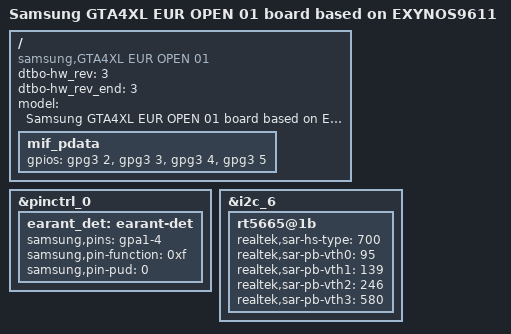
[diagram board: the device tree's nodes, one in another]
/*
 * SAMSUNG EXYNOS9610 board device tree source
 *
 * Copyright (c) 2018 Samsung Electronics Co., Ltd.
 *		http://www.samsung.com
 *
 * This program is free software; you can redistribute it and/or modify
 * it under the terms of the GNU General Public License version 2 as
 * published by the Free Software Foundation.
 */

/dts-v1/;
/plugin/;

#include "exynos9611-gta4xl_common.dtsi"
#include "battery_data_gta4xl_common.dtsi"
#include "exynos9611-gta4xl_sensorhub_00.dtsi"
#include "exynos9611-gta4xl_eur_open_gpio_03.dtsi"

/ {
	compatible = "samsung,GTA4XL EUR OPEN 01", "samsung,EXYNOS9611";

	dtbo-hw_rev = <3>;
    dtbo-hw_rev_end = <3>;


	fragment@model {
		target-path = "/";
		__overlay__ {
			#address-cells = <2>;
			#size-cells = <1>;

			model = "Samsung GTA4XL EUR OPEN 01 board based on EXYNOS9611";

			mif_pdata {
				/* GPIOs for HW REV */
				/* XGPIO26-AP_REV0, XGPIO27-AP_REV1, XGPIO28-AP_REV2, XGPIO29-AP_REV3 */
				gpios = <&gpg3 2 0>, <&gpg3 3 0>, <&gpg3 4 0>, <&gpg3 5 0>;
				pinctrl-names = "default";
			};
		}; /* end of __overlay__ */
	}; /* end of fragment */
}; /* end of root */

&pinctrl_0 {
	earant_det: earant-det {
		samsung,pins ="gpa1-4";
		samsung,pin-function = <0xf>;
		samsung,pin-pud = <0>;
	};
};

&i2c_6 {
	rt5665@1b {
		realtek,sar-hs-type = <700>;
		realtek,sar-pb-vth0 = <95>;
		realtek,sar-pb-vth1 = <139>;
		realtek,sar-pb-vth2 = <246>;
		realtek,sar-pb-vth3 = <580>;
	};
};
